# STM32F303 register map
File version: 1.7
Registers are 32-bit, read-write, reset 0x0 unless marked. A register's access mark holds for its fields unless they carry their own. Offsets are from the block's base; [hi:lo] are bit positions; {n}, {i} and the like mark numbered series.

## EXTI — External interrupt/event controller
Base 0x40010400
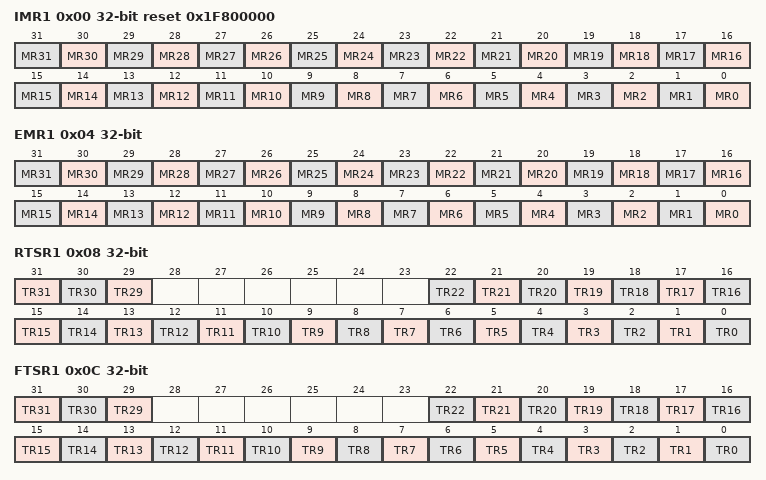
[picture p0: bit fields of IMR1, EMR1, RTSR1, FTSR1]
0x00 IMR1 reset 0x1F800000 — Interrupt mask register
  [n] MR{n} (n=0..31) — Interrupt Mask on line {n}
0x04 EMR1 — Event mask register
  [n] MR{n} (n=0..31) — Event Mask on line {n}
0x08 RTSR1 — Rising Trigger selection register
  [31] TR31 — Rising trigger event configuration of line 31
  [30] TR30 — Rising trigger event configuration of line 30
  [29] TR29 — Rising trigger event configuration of line 29
  [n] TR{n} (n=0..22) — Rising trigger event configuration of line {n}
0x0C FTSR1 — Falling Trigger selection register
  [31] TR31 — Falling trigger event configuration of line 31
  [30] TR30 — Falling trigger event configuration of line 30.
  [29] TR29 — Falling trigger event configuration of line 29
  [n] TR{n} (n=0..22) — Falling trigger event configuration of line {n}
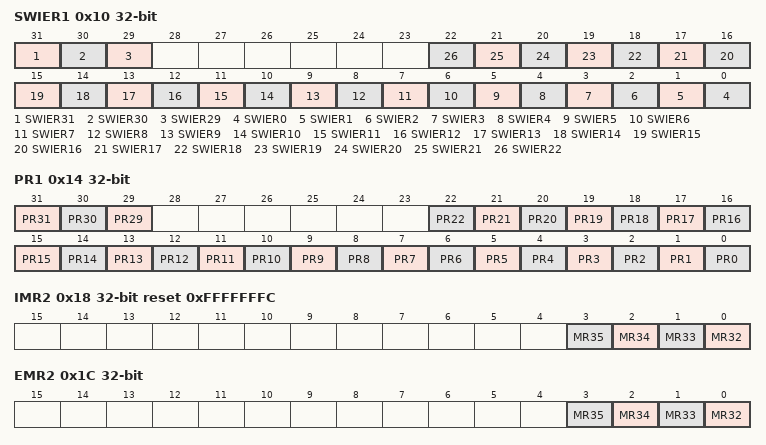
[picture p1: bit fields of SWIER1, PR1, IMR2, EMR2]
0x10 SWIER1 — Software interrupt event register
  [31] SWIER31 — Software Interrupt on line 319
  [30] SWIER30 — Software Interrupt on line 309
  [29] SWIER29 — Software Interrupt on line 29
  [n] SWIER{n} (n=0..22) — Software Interrupt on line {n}
0x14 PR1 — Pending register
  [31] PR31 — Pending bit 31
  [30] PR30 — Pending bit 30
  [29] PR29 — Pending bit 29
  [n] PR{n} (n=0..22) — Pending bit {n}
0x18 IMR2 reset 0xFFFFFFFC — Interrupt mask register
  [n-32] MR{n} (n=32..35) — Interrupt Mask on external/internal line {n}
0x1C EMR2 — Event mask register
  [n-32] MR{n} (n=32..35) — Event mask on external/internal line {n}
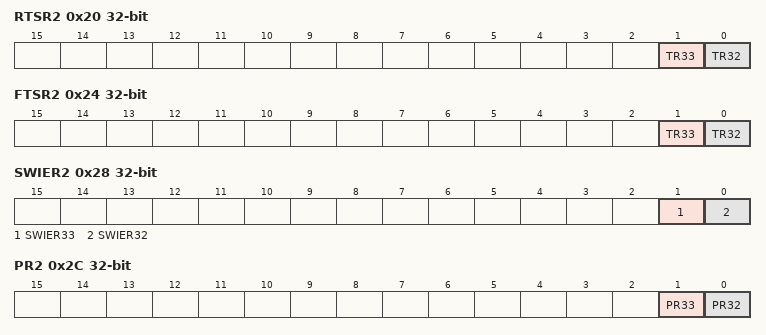
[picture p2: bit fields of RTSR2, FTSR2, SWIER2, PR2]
0x20 RTSR2 — Rising Trigger selection register
  [1] TR33 — Rising trigger event configuration bit of line 33
  [0] TR32 — Rising trigger event configuration bit of line 32
0x24 FTSR2 — Falling Trigger selection register
  [1] TR33 — Falling trigger event configuration bit of line 33
  [0] TR32 — Falling trigger event configuration bit of line 32
0x28 SWIER2 — Software interrupt event register
  [1] SWIER33 — Software interrupt on line 33
  [0] SWIER32 — Software interrupt on line 32
0x2C PR2 — Pending register
  [1] PR33 — Pending bit on line 33
  [0] PR32 — Pending bit on line 32

## PWR — Power control
Base 0x40007000
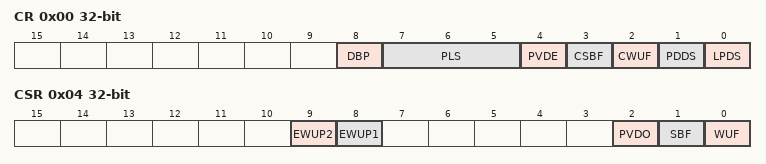
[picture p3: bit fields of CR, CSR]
0x00 CR — power control register
  [8] DBP — Disable backup domain write protection
  [7:5] PLS — PVD level selection
  [4] PVDE — Power voltage detector enable
  [3] CSBF — Clear standby flag
  [2] CWUF — Clear wakeup flag
  [1] PDDS — Power down deepsleep
  [0] LPDS — Low-power deep sleep
0x04 CSR access per field — power control/status register
  [9] EWUP2 rw — Enable WKUP2 pin
  [8] EWUP1 rw — Enable WKUP1 pin
  [2] PVDO ro — PVD output
  [1] SBF ro — Standby flag
  [0] WUF ro — Wakeup flag

## IWDG — Independent watchdog
Base 0x40003000
0x00 KR wo — Key register
  [15:0] KEY — Key value
0x04 PR — Prescaler register
  [2:0] PR — Prescaler divider
0x08 RLR reset 0xFFF — Reload register
  [11:0] RL — Watchdog counter reload value
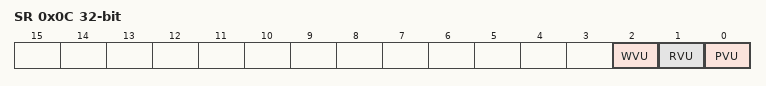
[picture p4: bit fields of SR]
0x0C SR ro — Status register
  [2] WVU — Watchdog counter window value update
  [1] RVU — Watchdog counter reload value update
  [0] PVU — Watchdog prescaler value update
0x10 WINR reset 0xFFF — Window register
  [11:0] WIN — Watchdog counter window value

## WWDG — Window watchdog
Base 0x40002C00
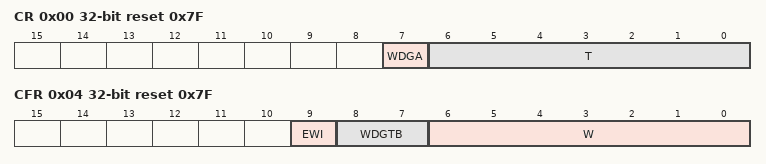
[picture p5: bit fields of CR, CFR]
0x00 CR reset 0x7F — Control register
  [7] WDGA — Activation bit
  [6:0] T — 7-bit counter
0x04 CFR reset 0x7F — Configuration register
  [9] EWI — Early wakeup interrupt
  [8:7] WDGTB — Timer base
  [6:0] W — 7-bit window value
0x08 SR — Status register
  [0] EWIF — Early wakeup interrupt flag

## DBGMCU — Debug support
Base 0xE0042000
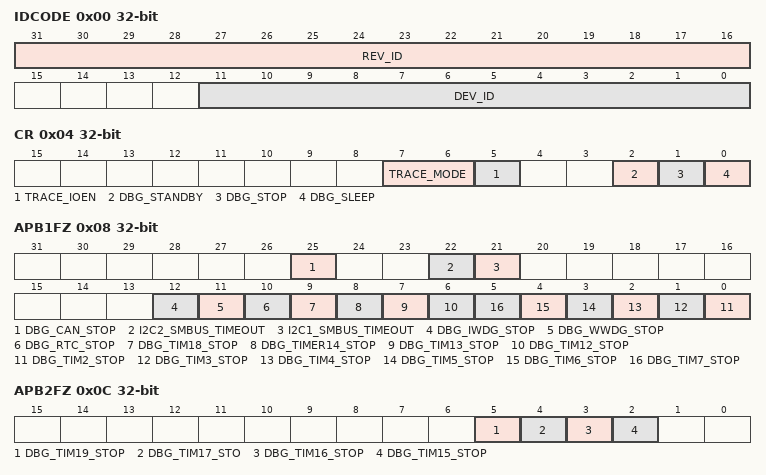
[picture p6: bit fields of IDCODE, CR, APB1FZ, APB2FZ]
0x00 IDCODE ro — MCU Device ID Code Register
  [31:16] REV_ID — Revision Identifier
  [11:0] DEV_ID — Device Identifier
0x04 CR — Debug MCU Configuration Register
  [7:6] TRACE_MODE — Trace pin assignment control
  [5] TRACE_IOEN — Trace pin assignment control
  [2] DBG_STANDBY — Debug Standby Mode
  [1] DBG_STOP — Debug Stop Mode
  [0] DBG_SLEEP — Debug Sleep mode
0x08 APB1FZ — APB Low Freeze Register
  [25] DBG_CAN_STOP — Debug CAN stopped when core is halted
  [22] I2C2_SMBUS_TIMEOUT — SMBUS timeout mode stopped when Core is halted
  [21] I2C1_SMBUS_TIMEOUT — SMBUS timeout mode stopped when Core is halted
  [12] DBG_IWDG_STOP — Debug Independent Wachdog stopped when Core is halted
  [11] DBG_WWDG_STOP — Debug Window Wachdog stopped when Core is halted
  [10] DBG_RTC_STOP — Debug RTC stopped when Core is halted
  [9] DBG_TIM18_STOP — Debug Timer 18 stopped when Core is halted
  [8] DBG_TIMER14_STOP — Debug Timer 14 stopped when Core is halted
  [7] DBG_TIM13_STOP — Debug Timer 13 stopped when Core is halted
  [6] DBG_TIM12_STOP — Debug Timer 12 stopped when Core is halted
  [n-2] DBG_TIM{n}_STOP (n=2..7) — Debug Timer {n} stopped when Core is halted
0x0C APB2FZ — APB High Freeze Register
  [5] DBG_TIM19_STOP — Debug Timer 19 stopped when Core is halted
  [4] DBG_TIM17_STO — Debug Timer 17 stopped when Core is halted
  [3] DBG_TIM16_STOP — Debug Timer 16 stopped when Core is halted
  [2] DBG_TIM15_STOP — Debug Timer 15 stopped when Core is halted

## FPU — Floting point unit
Base 0xE000EF34
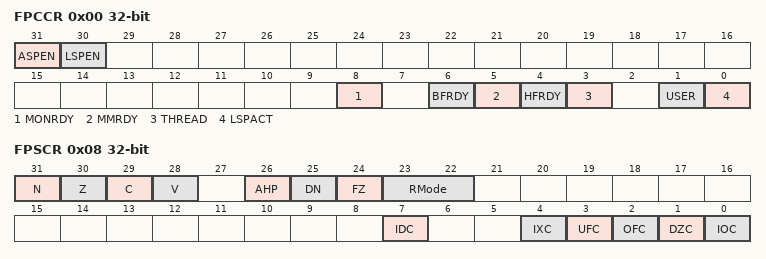
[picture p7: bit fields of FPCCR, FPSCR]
0x00 FPCCR — Floating-point context control register
  [31] ASPEN, [30] LSPEN, [8] MONRDY, [6] BFRDY, [5] MMRDY, [4] HFRDY, [3] THREAD, [1] USER, [0] LSPACT
0x04 FPCAR — Floating-point context address register
  [31:3] ADDRESS — Location of unpopulated floating-point
0x08 FPSCR — Floating-point status control register
  [31] N — Negative condition code flag
  [30] Z — Zero condition code flag
  [29] C — Carry condition code flag
  [28] V — Overflow condition code flag
  [26] AHP — Alternative half-precision control bit
  [25] DN — Default NaN mode control bit
  [24] FZ — Flush-to-zero mode control bit:
  [23:22] RMode — Rounding Mode control field
  [7] IDC — Input denormal cumulative exception bit.
  [4] IXC — Inexact cumulative exception bit
  [3] UFC — Underflow cumulative exception bit
  [2] OFC — Overflow cumulative exception bit
  [1] DZC — Division by zero cumulative exception bit.
  [0] IOC — Invalid operation cumulative exception bit

## MPU — Memory protection unit
Base 0xE000ED90
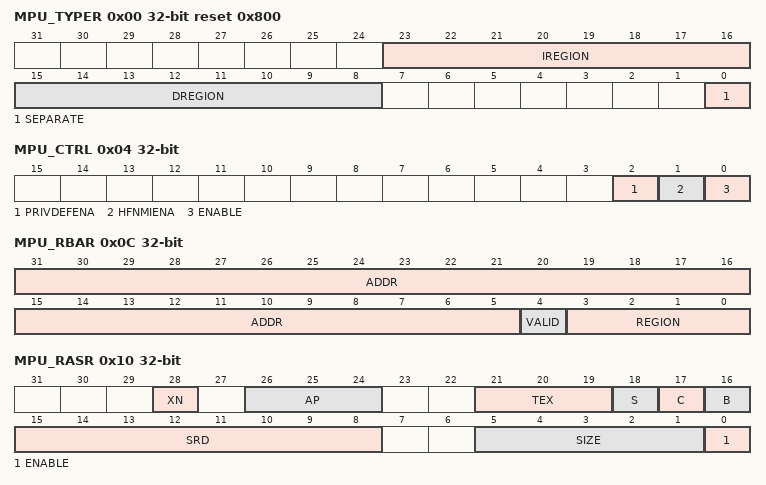
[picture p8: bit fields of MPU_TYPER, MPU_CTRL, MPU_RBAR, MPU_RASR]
0x00 MPU_TYPER ro reset 0x800 — MPU type register
  [23:16] IREGION — Number of MPU instruction regions
  [15:8] DREGION — Number of MPU data regions
  [0] SEPARATE — Separate flag
0x04 MPU_CTRL ro — MPU control register
  [2] PRIVDEFENA — Enable priviliged software access to default memory map
  [1] HFNMIENA — Enables the operation of MPU during hard fault
  [0] ENABLE — Enables the MPU
0x08 MPU_RNR — MPU region number register
  [7:0] REGION — MPU region
0x0C MPU_RBAR — MPU region base address register
  [31:5] ADDR — Region base address field
  [4] VALID — MPU region number valid
  [3:0] REGION — MPU region field
0x10 MPU_RASR — MPU region attribute and size register
  [28] XN — Instruction access disable bit
  [26:24] AP — Access permission
  [21:19] TEX — memory attribute
  [18] S — Shareable memory attribute
  [17] C — memory attribute
  [16] B — memory attribute
  [15:8] SRD — Subregion disable bits
  [5:1] SIZE — Size of the MPU protection region
  [0] ENABLE — Region enable bit.

## STK — SysTick timer
Base 0xE000E010
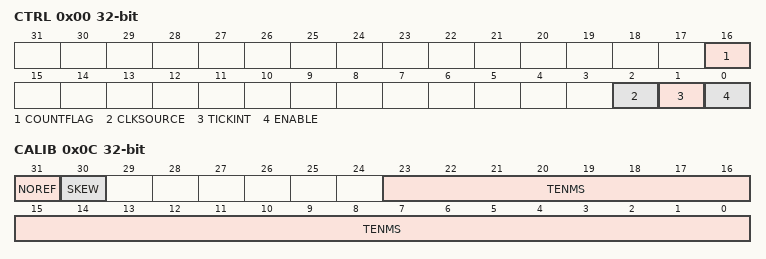
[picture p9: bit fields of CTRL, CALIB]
0x00 CTRL — SysTick control and status register
  [16] COUNTFLAG
  [2] CLKSOURCE — Clock source selection
  [1] TICKINT — SysTick exception request enable
  [0] ENABLE — Counter enable
0x04 LOAD — SysTick reload value register
  [23:0] RELOAD — RELOAD value
0x08 VAL — SysTick current value register
  [23:0] CURRENT — Current counter value
0x0C CALIB — SysTick calibration value register
  [31] NOREF — NOREF flag. Reads as zero
  [30] SKEW — SKEW flag: Indicates whether the TENMS value is exact
  [23:0] TENMS — Calibration value

## FPU_CPACR — Floating point unit CPACR
Base 0xE000ED88
0x00 CPACR — Coprocessor access control register
  [23:20] CP

## SCB_ACTRL — System control block ACTLR
Base 0xE000E008
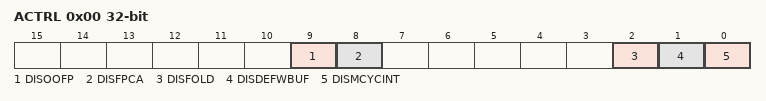
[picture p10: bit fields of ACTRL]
0x00 ACTRL — Auxiliary control register
  [9] DISOOFP, [8] DISFPCA, [2] DISFOLD, [1] DISDEFWBUF, [0] DISMCYCINT
